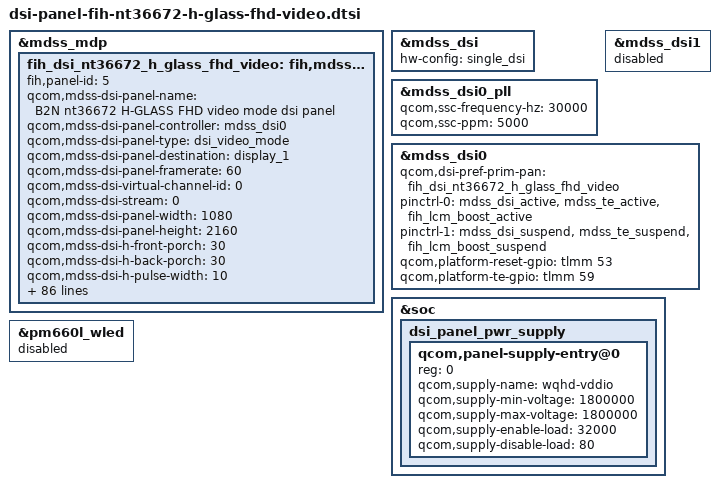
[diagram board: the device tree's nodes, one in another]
/* Copyright (c) 2013, The Linux Foundation. All rights reserved.
 *
 * This program is free software; you can redistribute it and/or modify
 * it under the terms of the GNU General Public License version 2 and
 * only version 2 as published by the Free Software Foundation.
 *
 * This program is distributed in the hope that it will be useful,
 * but WITHOUT ANY WARRANTY; without even the implied warranty of
 * MERCHANTABILITY or FITNESS FOR A PARTICULAR PURPOSE.  See the
 * GNU General Public License for more details.
 */

/*---------------------------------------------------------------------------
 * This file is autogenerated file using gcdb parser. Please do not edit it.
 * Update input XML file to add a new entry or update variable in this file
 * VERSION = "1.0"
 *---------------------------------------------------------------------------*/
&mdss_mdp {
	fih_dsi_nt36672_h_glass_fhd_video: fih,mdss_dsi_nt36672_h_glass_fhd_video {
		fih,panel-id = <5>;
		qcom,mdss-dsi-panel-name = "B2N nt36672 H-GLASS FHD video mode dsi panel";
		qcom,mdss-dsi-panel-controller = <&mdss_dsi0>;
		qcom,mdss-dsi-panel-type = "dsi_video_mode";
		qcom,mdss-dsi-panel-destination = "display_1";
		qcom,mdss-dsi-panel-framerate = <60>;
		qcom,mdss-dsi-virtual-channel-id = <0>;
		qcom,mdss-dsi-stream = <0>;
		qcom,mdss-dsi-panel-width = <1080>;
		qcom,mdss-dsi-panel-height = <2160>;
		qcom,mdss-dsi-h-front-porch = <30>;
		qcom,mdss-dsi-h-back-porch = <30>;
		qcom,mdss-dsi-h-pulse-width = <10>;
		qcom,mdss-dsi-h-sync-skew = <0>;
		qcom,mdss-dsi-v-front-porch = <10>;
		qcom,mdss-dsi-v-back-porch = <5>;
		qcom,mdss-dsi-v-pulse-width = <2>;
		qcom,mdss-dsi-h-left-border = <0>;
		qcom,mdss-dsi-h-right-border = <0>;
		qcom,mdss-dsi-v-top-border = <0>;
		qcom,mdss-dsi-v-bottom-border = <0>;
		qcom,mdss-dsi-bpp = <24>;
		qcom,mdss-dsi-color-order = "rgb_swap_rgb";
		qcom,mdss-dsi-underflow-color = <0xff>;
		qcom,mdss-dsi-border-color = <0>;
		qcom,mdss-dsi-on-command = [
			15 01 00 00 00 00 02 FF 20
			15 01 00 00 00 00 02 FB 01
			15 01 00 00 00 00 02 01 33
			15 01 00 00 00 00 02 06 96
			15 01 00 00 00 00 02 07 9C
			15 01 00 00 00 00 02 0E 2D
			15 01 00 00 00 00 02 0F 2C
			15 01 00 00 00 00 02 1D 33
			15 01 00 00 00 00 02 68 03
			15 01 00 00 00 00 02 6D 66
			15 01 00 00 00 00 02 69 99
			15 01 00 00 00 00 02 89 0F
			15 01 00 00 00 00 02 95 D7
			15 01 00 00 00 00 02 96 D7
			15 01 00 00 00 00 02 FF 24
			15 01 00 00 00 00 02 FB 01
			15 01 00 00 00 00 02 00 00
			15 01 00 00 00 00 02 01 00
			15 01 00 00 00 00 02 02 00
			15 01 00 00 00 00 02 03 00
			15 01 00 00 00 00 02 04 11
			15 01 00 00 00 00 02 05 00
			15 01 00 00 00 00 02 06 0C
			15 01 00 00 00 00 02 07 1B
			15 01 00 00 00 00 02 08 03
			15 01 00 00 00 00 02 09 04
			15 01 00 00 00 00 02 0A 19
			15 01 00 00 00 00 02 0B 00
			15 01 00 00 00 00 02 0C 14
			15 01 00 00 00 00 02 0D 16
			15 01 00 00 00 00 02 0E 18
			15 01 00 00 00 00 02 0F 17
			15 01 00 00 00 00 02 10 15
			15 01 00 00 00 00 02 11 13
			15 01 00 00 00 00 02 12 00
			15 01 00 00 00 00 02 13 00
			15 01 00 00 00 00 02 14 00
			15 01 00 00 00 00 02 15 00
			15 01 00 00 00 00 02 16 00
			15 01 00 00 00 00 02 17 00
			15 01 00 00 00 00 02 18 01
			15 01 00 00 00 00 02 19 1B
			15 01 00 00 00 00 02 1A 03
			15 01 00 00 00 00 02 1B 04
			15 01 00 00 00 00 02 1C 19
			15 01 00 00 00 00 02 1D 00
			15 01 00 00 00 00 02 1E 14
			15 01 00 00 00 00 02 1F 16
			15 01 00 00 00 00 02 20 18
			15 01 00 00 00 00 02 21 17
			15 01 00 00 00 00 02 22 15
			15 01 00 00 00 00 02 23 13
			15 01 00 00 00 00 02 2F 02
			15 01 00 00 00 00 02 30 03
			15 01 00 00 00 00 02 31 02
			15 01 00 00 00 00 02 32 03
			15 01 00 00 00 00 02 33 02
			15 01 00 00 00 00 02 34 02
			15 01 00 00 00 00 02 35 00
			15 01 00 00 00 00 02 36 01
			15 01 00 00 00 00 02 37 20
			15 01 00 00 00 00 02 38 67
			15 01 00 00 00 00 02 39 67
			15 01 00 00 00 00 02 3F 67
			15 01 00 00 00 00 02 60 10
			15 01 00 00 00 00 02 68 C2
			15 01 00 00 00 00 02 6F 10
			15 01 00 00 00 00 02 78 80
			15 01 00 00 00 00 02 79 22
			15 01 00 00 00 00 02 7A 00
			15 01 00 00 00 00 02 7B 9C
			15 01 00 00 00 00 02 7C 80
			15 01 00 00 00 00 02 7D 05
			15 01 00 00 00 00 02 7E 00
			15 01 00 00 00 00 02 80 44
			15 01 00 00 00 00 02 81 05
			15 01 00 00 00 00 02 92 74
			15 01 00 00 00 00 02 93 0C
			15 01 00 00 00 00 02 94 2E
			15 01 00 00 00 00 02 99 33
			15 01 00 00 00 00 02 9B FF
			15 01 00 00 00 00 02 A3 91
			15 01 00 00 00 00 02 B3 2A
			15 01 00 00 00 00 02 B4 94
			15 01 00 00 00 00 02 B5 04
			15 01 00 00 00 00 02 D6 04
			15 01 00 00 00 00 02 D7 5D
			15 01 00 00 00 00 02 D8 13
			15 01 00 00 00 00 02 D9 00
			15 01 00 00 00 00 02 DC 00
			15 01 00 00 00 00 02 DD 02
			15 01 00 00 00 00 02 DE 11
			15 01 00 00 00 00 02 DF 3A
			15 01 00 00 00 00 02 E0 39
			15 01 00 00 00 00 02 E9 00
			15 01 00 00 00 00 02 ED 40
			15 01 00 00 00 00 02 EE 00
			15 01 00 00 00 00 02 EF 54
			15 01 00 00 00 00 02 F0 01
			15 01 00 00 00 00 02 73 1F
			15 01 00 00 00 00 02 75 1F
			15 01 00 00 00 00 02 82 13
			15 01 00 00 00 00 02 83 22
			15 01 00 00 00 00 02 84 31
			15 01 00 00 00 00 02 85 00
			15 01 00 00 00 00 02 86 00
			15 01 00 00 00 00 02 87 00
			15 01 00 00 00 00 02 88 13
			15 01 00 00 00 00 02 89 22
			15 01 00 00 00 00 02 8A 31
			15 01 00 00 00 00 02 8B 00
			15 01 00 00 00 00 02 8C 00
			15 01 00 00 00 00 02 8D 00
			15 01 00 00 00 00 02 8E F4
			15 01 00 00 00 00 02 8F 01
			
			/***********************/
			/* Gamma Setting START */
			/***********************/			
			//page selection cmd start
			15 01 00 00 00 00 02 FF 20
			15 01 00 00 00 00 02 FB 01
			//page selection cmd end
			//R(+) MCR cmd
			39 01 00 00 00 00 11 B0 00 00 00 27 00 5D 00 84 00 A4 00 BE 00 D4 00 E7
			39 01 00 00 00 00 11 B1 00 F9 01 31 01 59 01 98 01 C4 02 0A 02 3D 02 40
			39 01 00 00 00 00 11 B2 02 74 02 AD 02 D5 03 03 03 26 03 4C 03 5B 03 68
			39 01 00 00 00 00 0D B3 03 77 03 89 03 9D 03 B5 03 C7 03 FF
			//G(+) MCR cmd
			39 01 00 00 00 00 11 B4 00 00 00 27 00 5D 00 84 00 A4 00 BE 00 D4 00 E7
			39 01 00 00 00 00 11 B5 00 F9 01 31 01 59 01 98 01 C4 02 0A 02 3D 02 40
			39 01 00 00 00 00 11 B6 02 74 02 AD 02 D5 03 03 03 26 03 4C 03 5B 03 68
			39 01 00 00 00 00 0D B7 03 77 03 89 03 9D 03 B5 03 C7 03 FF
			//B(+) MCR cmd
			39 01 00 00 00 00 11 B8 00 00 00 27 00 5D 00 84 00 A4 00 BE 00 D4 00 E7
			39 01 00 00 00 00 11 B9 00 F9 01 31 01 59 01 98 01 C4 02 0A 02 3D 02 40
			39 01 00 00 00 00 11 BA 02 74 02 AD 02 D5 03 03 03 26 03 4C 03 5B 03 68
			39 01 00 00 00 00 0D BB 03 77 03 89 03 9D 03 B5 03 C7 03 FF
			//page selection cmd start
			15 01 00 00 00 00 02 FF 21
			15 01 00 00 00 00 02 FB 01
			//page selection cmd end
			//R(-) MCR cmd
			39 01 00 00 00 00 11 B0 00 00 00 27 00 5D 00 84 00 A4 00 BE 00 D4 00 E7
			39 01 00 00 00 00 11 B1 00 F9 01 31 01 59 01 98 01 C4 02 0A 02 3D 02 40
			39 01 00 00 00 00 11 B2 02 74 02 AD 02 D5 03 03 03 26 03 4C 03 5B 03 68
			39 01 00 00 00 00 0D B3 03 77 03 89 03 9D 03 B5 03 C7 03 FF
			//G(+) MCR cmd
			39 01 00 00 00 00 11 B4 00 00 00 27 00 5D 00 84 00 A4 00 BE 00 D4 00 E7
			39 01 00 00 00 00 11 B5 00 F9 01 31 01 59 01 98 01 C4 02 0A 02 3D 02 40
			39 01 00 00 00 00 11 B6 02 74 02 AD 02 D5 03 03 03 26 03 4C 03 5B 03 68
			39 01 00 00 00 00 0D B7 03 77 03 89 03 9D 03 B5 03 C7 03 FF
			//B(+) MCR cmd
			39 01 00 00 00 00 11 B8 00 00 00 27 00 5D 00 84 00 A4 00 BE 00 D4 00 E7
			39 01 00 00 00 00 11 B9 00 F9 01 31 01 59 01 98 01 C4 02 0A 02 3D 02 40
			39 01 00 00 00 00 11 BA 02 74 02 AD 02 D5 03 03 03 26 03 4C 03 5B 03 68
			39 01 00 00 00 00 0D BB 03 77 03 89 03 9D 03 B5 03 C7 03 FF			
			/***********************/
			/* Gamma Setting END   */
			/***********************/	
						
			15 01 00 00 00 00 02 FF 25
			15 01 00 00 00 00 02 FB 01
			15 01 00 00 00 00 02 0A 81
			15 01 00 00 00 00 02 0B CE
			15 01 00 00 00 00 02 0C 01
			15 01 00 00 00 00 02 17 82
			15 01 00 00 00 00 02 19 0E
			15 01 00 00 00 00 02 21 1C
			15 01 00 00 00 00 02 22 1C
			15 01 00 00 00 00 02 24 74
			15 01 00 00 00 00 02 25 74
			15 01 00 00 00 00 02 30 1D
			15 01 00 00 00 00 02 3F 13
			15 01 00 00 00 00 02 40 03
			15 01 00 00 00 00 02 62 3F
			15 01 00 00 00 00 02 63 83
			15 01 00 00 00 00 02 65 00
			15 01 00 00 00 00 02 66 5D
			15 01 00 00 00 00 02 67 12
			15 01 00 00 00 00 02 68 50
			15 01 00 00 00 00 02 69 10
			15 01 00 00 00 00 02 6D 0D
			15 01 00 00 00 00 02 6E 48
			15 01 00 00 00 00 02 71 5D
			15 01 00 00 00 00 02 72 65
			15 01 00 00 00 00 02 73 3B
			15 01 00 00 00 00 02 74 90
			15 01 00 00 00 00 02 77 63
			15 01 00 00 00 00 02 78 25
			15 01 00 00 00 00 02 7E 1D
			15 01 00 00 00 00 02 7F 08
			15 01 00 00 00 00 02 82 00
			15 01 00 00 00 00 02 86 4D
			15 01 00 00 00 00 02 8F 04
			15 01 00 00 00 00 02 C3 03
			15 01 00 00 00 00 02 D0 80
			15 01 00 00 00 00 02 D7 80
			15 01 00 00 00 00 02 D8 80
			15 01 00 00 00 00 02 FF 26
			15 01 00 00 00 00 02 FB 01
			15 01 00 00 00 00 02 06 C8
			15 01 00 00 00 00 02 0C 0B
			15 01 00 00 00 00 02 0F 06
			15 01 00 00 00 00 02 10 07
			15 01 00 00 00 00 02 12 B4
			15 01 00 00 00 00 02 19 17
			15 01 00 00 00 00 02 1A 20
			15 01 00 00 00 00 02 1D 16
			15 01 00 00 00 00 02 1E A7
			15 01 00 00 00 00 02 81 1C
			15 01 00 00 00 00 02 85 01
			15 01 00 00 00 00 02 88 10
			15 01 00 00 00 00 02 8A 1A
			15 01 00 00 00 00 02 8C 44
			15 01 00 00 00 00 02 8D 33
			15 01 00 00 00 00 02 8E 22
			15 01 00 00 00 00 02 8F 22
			15 01 00 00 00 00 02 90 33
			15 01 00 00 00 00 02 91 44
			15 01 00 00 00 00 02 99 20
			15 01 00 00 00 00 02 FF 27
			15 01 00 00 00 00 02 FB 01
			15 01 00 00 00 00 02 13 08
			15 01 00 00 00 00 02 14 43
			15 01 00 00 00 00 02 16 B8
			15 01 00 00 00 00 02 17 B8
			15 01 00 00 00 00 02 7A 02
			15 01 00 00 00 00 02 FF 10
			05 01 00 00 78 00 02 11 00
			05 01 00 00 00 00 02 29 00
			15 01 00 00 00 00 02 53 2C
			15 01 00 00 00 00 02 5E 0A
		];
		qcom,mdss-dsi-off-command = [
			05 01 00 00 0A 00 02 28 00
			05 01 00 00 96 00 02 10 00
		];
		qcom,suspend-ulps-enabled;

		qcom,mdss-dsi-on-command-state = "dsi_lp_mode";
		qcom,mdss-dsi-off-command-state = "dsi_hs_mode";
		qcom,mdss-dsi-h-sync-pulse = <1>;
		qcom,mdss-dsi-traffic-mode = "burst_mode";
		qcom,mdss-dsi-lane-map = "lane_map_0123";
		qcom,mdss-dsi-bllp-eof-power-mode;
		qcom,mdss-dsi-bllp-power-mode;
		qcom,mdss-dsi-lp11-init;
		qcom,mdss-dsi-init-delay-us = <5>;
		qcom,mdss-dsi-lane-0-state;
		qcom,mdss-dsi-lane-1-state;
		qcom,mdss-dsi-lane-2-state;
		qcom,mdss-dsi-lane-3-state;
		qcom,mdss-dsi-t-clk-post = <0x0D>;
		qcom,mdss-dsi-t-clk-pre = <0x30>;
		qcom,mdss-dsi-dma-trigger = "trigger_sw";
		qcom,mdss-dsi-mdp-trigger = "none";
		qcom,mdss-dsi-reset-sequence = <0 5>, <1 10>;

		qcom,mdss-pan-physical-width-dimension = <68>;
		qcom,mdss-pan-physical-height-dimension = <136>;
		qcom,mdss-pan-physical-width-dimension-full = <6804>;
		qcom,mdss-pan-physical-height-dimension-full = <13608>;

		/* SW4-HL-Display-EliminateMostDsiError-00+{_20170216 */
		qcom,mdss-dsi-tx-eot-append;
		/* SW4-HL-Display-EliminateMostDsiError-00+}_20170216 */

		/* SW4-HL-Display-DynamicReadWriteRegister-00+{_20160729 */
		fih,mdss-dsi-write-reg-command = [
			39 01 00 00 00 00 04 FF 78 07 00
		];

		fih,mdss-dsi-write-reg-command-state = "dsi_lp_mode";
		/* SW4-HL-Display-DynamicReadWriteRegister-00+}_20160729 */

		/* SW4-HL-Display-ImplementCABC-00+{_20180829 */
		qcom,mdss-dsi-cabc-off-command = [
			39 00 00 00 00 00 02 FF 10
			39 01 00 00 00 00 02 55 00
		];

		qcom,mdss-dsi-cabc-ui-command = [
			39 00 00 00 00 00 02 FF 10
			39 01 00 00 00 00 02 55 01
		];

		qcom,mdss-dsi-cabc-still-command = [
			39 00 00 00 00 00 02 FF 10
			39 01 00 00 00 00 02 55 02
		];

		qcom,mdss-dsi-cabc-moving-command = [
			39 00 00 00 00 00 02 FF 10
			39 01 00 00 00 00 02 55 03
		];

		qcom,mdss-dsi-cabc-off-command-state = "dsi_hs_mode";
		qcom,mdss-dsi-cabc-ui-command-state = "dsi_hs_mode";
		qcom,mdss-dsi-cabc-still-command-state = "dsi_hs_mode";
		qcom,mdss-dsi-cabc-moving-command-state = "dsi_hs_mode";

		qcom,mdss-dsi-cabc-off-command-BeforeInit = [
			39 01 00 00 00 00 02 FF 10
			39 01 00 00 00 00 02 55 00
		];

		qcom,mdss-dsi-cabc-ui-command-BeforeInit = [
			39 01 00 00 00 00 02 FF 10
			39 01 00 00 00 00 02 55 01
		];

		qcom,mdss-dsi-cabc-still-command-BeforeInit = [
			39 01 00 00 00 00 02 FF 10
			39 01 00 00 00 00 02 55 02
		];

		qcom,mdss-dsi-cabc-moving-command-BeforeInit = [
			39 01 00 00 00 00 02 FF 10
			39 01 00 00 00 00 02 55 03
		];

		qcom,mdss-dsi-cabc-off-command-BeforeInit-state = "dsi_lp_mode";
		qcom,mdss-dsi-cabc-ui-command-BeforeInit-state = "dsi_lp_mode";
		qcom,mdss-dsi-cabc-still-command-BeforeInit-state = "dsi_lp_mode";
		qcom,mdss-dsi-cabc-moving-command-BeforeInit-state = "dsi_lp_mode";
		/* SW4-HL-Display-ImplementCABC-00+}_20180829 */
	};
};

&fih_dsi_nt36672_h_glass_fhd_video {
	qcom,mdss-dsi-panel-timings-phy-v2 = [
		24 1F 08 09 05 03 04 a0
		24 1F 08 09 05 03 04 a0
		24 1F 08 09 05 03 04 a0
		24 1F 08 09 05 03 04 a0
		24 1F 08 09 05 03 04 a0
	];
	//qcom,mdss-dsi-bl-pmic-control-type = "bl_ctrl_wled";
	qcom,mdss-dsi-bl-pmic-control-type = "bl_ctrl_dcs";
	qcom,mdss-dsi-bl-min-level = <1>;
	qcom,mdss-dsi-bl-max-level = <255>;
	qcom,panel-supply-entries = <&dsi_panel_pwr_supply>;
};

&mdss_dsi {
	hw-config = "single_dsi";
};

&mdss_dsi0_pll {
	qcom,ssc-frequency-hz = <30000>;
	qcom,ssc-ppm = <5000>;
};

&mdss_dsi1 {
	status = "disabled";
};


&mdss_dsi0 {
	qcom,dsi-pref-prim-pan = <&fih_dsi_nt36672_h_glass_fhd_video>;
	pinctrl-names = "mdss_default", "mdss_sleep";
	pinctrl-0 = <&mdss_dsi_active &mdss_te_active &fih_lcm_boost_active>;
	pinctrl-1 = <&mdss_dsi_suspend &mdss_te_suspend &fih_lcm_boost_suspend>;
	qcom,platform-reset-gpio = <&tlmm 53 0>;
	qcom,platform-te-gpio = <&tlmm 59 0>;
};

&soc {
	/delete-node/dsi_panel_pwr_supply;

	dsi_panel_pwr_supply: dsi_panel_pwr_supply {
		#address-cells = <1>;
		#size-cells = <0>;

		/* PM660 L11 */
		qcom,panel-supply-entry@0 {
			reg = <0>;
			qcom,supply-name = "wqhd-vddio";
			qcom,supply-min-voltage = <1800000>;
			qcom,supply-max-voltage = <1800000>;
			qcom,supply-enable-load = <32000>;
			qcom,supply-disable-load = <80>;
		};
	};
};

&pm660l_wled {
	status = "disabled";
};
